AUTOSAR XML (schema 00044)
package /ComponentTypes
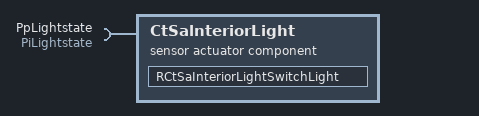
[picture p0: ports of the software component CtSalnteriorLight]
  sensor actuator sw component type CtSalnteriorLight
    require port PpLightstate: nonqueued-receiver-com-spec{data-element=DeLightstate, init-value=constant-reference=Clightoff}, required-interface=PiLightstate
    behavior CtSalnteriorLight_InternalBehavior: supports-multiple-instantiation=true
      data received event DRT_RCtSaInteriorLightSwitchLight_PpLightstate_DeLightstate: start-on-event=RCtSaInteriorLightSwitchLight, data=PpLightstate.DeLightstate
      runnable RCtSaInteriorLightSwitchLight
        data-receive-point-by-arguments:
          access REC_PpLightstate_DeLightstate: accessed-variable=PpLightstate.DeLightstate
  swc implementation CtSalnteriorLight_Implementation: behavior=CtSalnteriorLight_InternalBehavior
